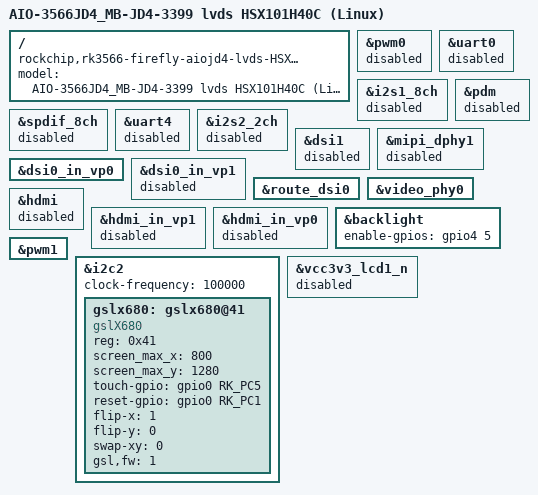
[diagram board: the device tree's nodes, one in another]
// SPDX-License-Identifier: (GPL-2.0+ OR MIT)
/*
 * Copyright (c) 2020 Rockchip Electronics Co., Ltd.
 *
 */

 /dts-v1/;



#include "rk3566-firefly-aiojd4_MB-JD4-3399.dtsi"
#include "lcd-mipi-to-lvds-HSX101H40C.dtsi"

/ {
    model = "AIO-3566JD4_MB-JD4-3399 lvds HSX101H40C (Linux)";
    compatible = "rockchip,rk3566-firefly-aiojd4-lvds-HSX101H40C", "rockchip,rk3566";

};

// disabled some multiplex gpios
&pwm0{
	status = "disabled";
};
&uart0{
	status = "disabled";
};
&i2s1_8ch{
	status = "disabled";
};
&pdm{
	status = "disabled";
};
&spdif_8ch{
	status = "disabled";
};
&uart4{
	status = "disabled";
};

&i2s2_2ch{
	status = "disabled";
};

//disabled dsi1 
&dsi1{
    status = "disabled";
};
&mipi_dphy1 {
    status = "disabled";
};
&dsi0_in_vp0 {
    status = "disabled";
};
&dsi0_in_vp1 {
    status = "disabled";
};

//open dsi0 main
&route_dsi0 {
    status = "okay";
};
&video_phy0 {
    status = "okay";
};
&dsi0_in_vp0 {
    status = "okay";
};
&dsi0_in_vp1 {
    status = "disabled";
};

//disabled hdmi extend
&hdmi{
    status = "disabled";
};
&hdmi_in_vp1{
    status = "disabled";
};
&hdmi_in_vp0{
    status = "disabled";
};

// open backlight
&backlight {
        status = "okay";
		enable-gpios = <&gpio4 5 GPIO_ACTIVE_HIGH>;
};
&pwm1{
    status = "okay";
};

//open gslx680 tp
&i2c2 {
    status = "okay";
    clock-frequency = <100000>;
    //i2c-scl-rising-time-ns = <800>;
    //i2c-scl-falling-time-ns = <100>;#if 0
    gslx680: gslx680@41 {
        compatible = "gslX680";
        reg = <0x41>;
        screen_max_x = <800>;
        screen_max_y = <1280>;
        touch-gpio = <&gpio0 RK_PC5 IRQ_TYPE_LEVEL_LOW>;
        reset-gpio = <&gpio0 RK_PC1 GPIO_ACTIVE_HIGH>;
        flip-x = <1>;
        flip-y = <0>;
        swap-xy = <0>;
        gsl,fw = <1>;
    };
};
&vcc3v3_lcd1_n{
    status = "disabled";
};
